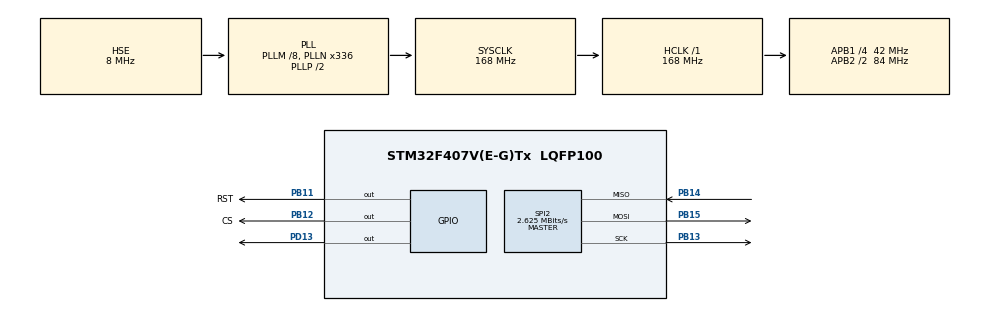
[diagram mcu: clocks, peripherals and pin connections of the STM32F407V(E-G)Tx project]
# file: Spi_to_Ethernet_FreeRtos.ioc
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FREERTOS.Tasks01=defaultTask,24,128,StartDefaultTask,Default,NULL,Dynamic,NULL,NULL
Mcu.Family=STM32F4
Mcu.Name=STM32F407V(E-G)Tx
Mcu.Package=LQFP100
NVIC.PriorityGroup=NVIC_PRIORITYGROUP_4
PA13.Mode=Trace_Asynchronous_SW
PA13.Signal=SYS_JTMS-SWDIO
PA14.Mode=Trace_Asynchronous_SW
PA14.Signal=SYS_JTCK-SWCLK
PB11.GPIO_Label=RST
PB11.GPIO_Speed=GPIO_SPEED_FREQ_HIGH
PB11.PinState=GPIO_PIN_SET
PB11.Signal=GPIO_Output
PB12.GPIO_Label=CS
PB12.GPIO_Speed=GPIO_SPEED_FREQ_HIGH
PB12.PinState=GPIO_PIN_SET
PB12.Signal=GPIO_Output
PB13.Mode=Full_Duplex_Master
PB13.Signal=SPI2_SCK
PB14.Mode=Full_Duplex_Master
PB14.Signal=SPI2_MISO
PB15.Mode=Full_Duplex_Master
PB15.Signal=SPI2_MOSI
PB3.Mode=Trace_Asynchronous_SW
PB3.Signal=SYS_JTDO-SWO
PD13.Signal=GPIO_Output
PH0-OSC_IN.Mode=HSE-External-Oscillator
PH0-OSC_IN.Signal=RCC_OSC_IN
PH1-OSC_OUT.Mode=HSE-External-Oscillator
PH1-OSC_OUT.Signal=RCC_OSC_OUT
ProjectManager.HeapSize=0x200
ProjectManager.StackSize=0x400
ProjectManager.TargetToolchain=STM32CubeIDE
RCC.48MHZClocksFreq_Value=48000000
RCC.AHBFreq_Value=168000000
RCC.APB1CLKDivider=RCC_HCLK_DIV4
RCC.APB1Freq_Value=42000000
RCC.APB1TimFreq_Value=84000000
RCC.APB2CLKDivider=RCC_HCLK_DIV2
RCC.APB2Freq_Value=84000000
RCC.APB2TimFreq_Value=168000000
RCC.CortexFreq_Value=168000000
RCC.HCLKFreq_Value=168000000
RCC.HSE_VALUE=8000000
RCC.HSI_VALUE=16000000
RCC.LSE_VALUE=32768
RCC.PLLM=8
RCC.PLLN=336
RCC.PLLQ=7
RCC.PLLSourceVirtual=RCC_PLLSOURCE_HSE
RCC.SYSCLKFreq_VALUE=168000000
RCC.SYSCLKSource=RCC_SYSCLKSOURCE_PLLCLK
RCC.VCOOutputFreq_Value=336000000
SPI2.BaudRatePrescaler=SPI_BAUDRATEPRESCALER_16
SPI2.CalculateBaudRate=2.625 MBits/s
SPI2.Direction=SPI_DIRECTION_2LINES
SPI2.Mode=SPI_MODE_MASTER
SPI2.VirtualType=VM_MASTER
VP_FREERTOS_VS_CMSIS_V2.Mode=CMSIS_V2
board=STM32F407G-DISC1

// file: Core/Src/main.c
/* USER CODE BEGIN Header */
/**
 ******************************************************************************
 * @file           : main.c
 * @brief          : Main program body
 ******************************************************************************
 * @attention
 *
 * Copyright (c) 2026 STMicroelectronics.
 * All rights reserved.
 *
 * This software is licensed under terms that can be found in the LICENSE file
 * in the root directory of this software component.
 * If no LICENSE file comes with this software, it is provided AS-IS.
 *
 ******************************************************************************
 */
/* USER CODE END Header */
#include "main.h"
#include "cmsis_os.h"

/* USER CODE BEGIN Includes */
#include "freertos.h"
#include "task.h"
#include "wizchip_conf.h"
#include "w5500.h"
#include "stdio.h"
#include "socket.h"
#include <string.h>
/* USER CODE END Includes */

SPI_HandleTypeDef hspi2;

/* Definitions for defaultTask */

/* USER CODE BEGIN PV */
TaskHandle_t T = NULL;
/* USER CODE END PV */

void SystemClock_Config(void);
static void MX_GPIO_Init(void);
static void MX_SPI2_Init(void);
void StartDefaultTask(void *argument);

/* USER CODE BEGIN 0 */
uint8_t tx ={'a'};

static void W5500_Select(void) {
	HAL_GPIO_WritePin(GPIOB, GPIO_PIN_12, GPIO_PIN_RESET);
}
static void W5500_Unselect(void) {
	HAL_GPIO_WritePin(GPIOB, GPIO_PIN_12, GPIO_PIN_SET);
}

static uint8_t W5500_ReadByte(void)
{
    uint8_t tx = 0xFF;
    uint8_t rx;

    HAL_SPI_TransmitReceive(&hspi2, &tx, &rx, 1, HAL_MAX_DELAY);

    return rx;
}

static void W5500_WriteByte(uint8_t tx) {
	HAL_SPI_Transmit(&hspi2, &tx, 1, HAL_MAX_DELAY);
}

static void W5500_ReadBuff(uint8_t *buff, uint16_t len)
{
    uint8_t dummy = 0xFF;

    while(len--)
    {
        HAL_SPI_TransmitReceive(&hspi2, &dummy, buff, 1, HAL_MAX_DELAY);
        buff++;
    }
}

static void W5500_WriteBuff(uint8_t *buff, uint16_t len) {
	HAL_SPI_Transmit(&hspi2, buff, len, HAL_MAX_DELAY);
}

static void W5500_Reset(void) {
	HAL_GPIO_WritePin(GPIOB, GPIO_PIN_11, GPIO_PIN_RESET);
	HAL_Delay(1000);
	HAL_GPIO_WritePin(GPIOB, GPIO_PIN_11, GPIO_PIN_SET);
	HAL_Delay(5);
}

int __io_putchar(int ch) { ITM_SendChar(ch); return ch; }

void ethertx(void *argument){
	uint8_t rxBuf[512]

	while(1)
	{
		switch(getSn_SR(0)) //// give connect in hercules then only entr the condiion ,whie debugging

			    {
			        case SOCK_ESTABLISHED:
			        {
			            static uint8_t sent = 0;

			            if(sent < 3)
			            {
			                char msg[] = "AJ\n\tData Arrived!!!\n";

			                send(0, (uint8_t *)msg, strlen(msg));

			                printf("AJ Sent\r\n");
			                sent ++;
			            }

			            break;
			        }

			        case SOCK_CLOSE_WAIT:
			            disconnect(0);
			            break;

			        case SOCK_CLOSED:
			            socket(0, Sn_MR_TCP, 5000, 0);
			            listen(0);
			            break;
			    }

       }
}

void Ether_init(void *argument){
	while(1)
	{	uint8_t tx_size[8] = { 2, 2, 2, 2, 2, 2, 2, 2 };
		uint8_t rx_size[8] = { 2, 2, 2, 2, 2, 2, 2, 2 };

		wiz_NetInfo net_info =
		{
		    .mac  = {0x00,0x08,0xDC,0x11,0x11,0x11},
		    .ip   = {192,168,5,50},
		    .sn   = {255,255,255,0},
		    .gw   = {192,168,5,1},
		    .dns  = {8,8,8,8},
		    .dhcp = NETINFO_STATIC
		};
	//
		W5500_Reset();

		reg_wizchip_cs_cbfunc(W5500_Select, W5500_Unselect);
		reg_wizchip_spi_cbfunc(W5500_ReadByte, W5500_WriteByte);
		reg_wizchip_spiburst_cbfunc(W5500_ReadBuff, W5500_WriteBuff);

		if (wizchip_init(tx_size, rx_size) == -1) {
			Error_Handler();
		}
		wizchip_setnetinfo(&net_info);
		uint8_t version = getVERSIONR();
		printf("VERSION = %d\r\n", version);
		wiz_NetInfo net;

		wizchip_getnetinfo(&net);

		printf("MAC : %02X:%02X:%02X:%02X:%02X:%02X\r\n",
		       net.mac[0], net.mac[1], net.mac[2],
		       net.mac[3], net.mac[4], net.mac[5]);

		printf("IP  : %d.%d.%d.%d\r\n",
		       net.ip[0], net.ip[1], net.ip[2], net.ip[3]);

		printf("SN  : %d.%d.%d.%d\r\n",
		       net.sn[0], net.sn[1], net.sn[2], net.sn[3]);

		printf("GW  : %d.%d.%d.%d\r\n",
		       net.gw[0], net.gw[1], net.gw[2], net.gw[3]);

		printf("DNS : %d.%d.%d.%d\r\n",
		       net.dns[0], net.dns[1], net.dns[2], net.dns[3]);
		uint8_t link_state;

		do
		{
		    ctlwizchip(CW_GET_PHYLINK, &link_state);
		    printf("PHY = %d\r\n", link_state);
		} while (link_state == PHY_LINK_OFF);

		printf("PHY = %d\r\n", link_state);
		socket(0, Sn_MR_TCP, 80, 0);
		listen(0);

		printf("TCP Server Started\r\n");
vTaskDelete(T);
	}
}
/* USER CODE END 0 */

int main(void)
{

  /* MCU Configuration--------------------------------------------------------*/

  /* Reset of all peripherals, Initializes the Flash interface and the Systick. */
  HAL_Init();

  /* Configure the system clock */
  SystemClock_Config();

  /* Initialize all configured peripherals */
  MX_GPIO_Init();
  MX_SPI2_Init();
  /* USER CODE BEGIN 2 */
  printf("printfworks\n");

  if (HAL_SPI_GetState(&hspi2) != HAL_SPI_STATE_READY)
  {
printf("fault\n");  }

xTaskCreate(Ether_init, "Ether_init", 100, NULL, 8, &T);
xTaskCreate(ethertx, "ethertx", 100, NULL, 7, NULL);
vTaskStartScheduler();
  /* USER CODE END 2 */

  /* Init scheduler */

  /* Create the thread(s) */
  /* creation of defaultTask */

  /* Start scheduler */

  /* We should never get here as control is now taken by the scheduler */

  /* Infinite loop */
	while (1) {

		}
}

void SystemClock_Config(void)
{
  RCC_OscInitTypeDef RCC_OscInitStruct = {0};
  RCC_ClkInitTypeDef RCC_ClkInitStruct = {0};

  /** Configure the main internal regulator output voltage
  */
  __HAL_RCC_PWR_CLK_ENABLE();
  __HAL_PWR_VOLTAGESCALING_CONFIG(PWR_REGULATOR_VOLTAGE_SCALE1);

  /** Initializes the RCC Oscillators according to the specified parameters
  * in the RCC_OscInitTypeDef structure.
  */
  RCC_OscInitStruct.OscillatorType = RCC_OSCILLATORTYPE_HSE;
  RCC_OscInitStruct.HSEState = RCC_HSE_ON;
  RCC_OscInitStruct.PLL.PLLState = RCC_PLL_ON;
  RCC_OscInitStruct.PLL.PLLSource = RCC_PLLSOURCE_HSE;
  RCC_OscInitStruct.PLL.PLLM = 8;
  RCC_OscInitStruct.PLL.PLLN = 336;
  RCC_OscInitStruct.PLL.PLLP = RCC_PLLP_DIV2;
  RCC_OscInitStruct.PLL.PLLQ = 7;
  if (HAL_RCC_OscConfig(&RCC_OscInitStruct) != HAL_OK)
  {
    Error_Handler();
  }

  /** Initializes the CPU, AHB and APB buses clocks
  */
  RCC_ClkInitStruct.ClockType = RCC_CLOCKTYPE_HCLK|RCC_CLOCKTYPE_SYSCLK
                              |RCC_CLOCKTYPE_PCLK1|RCC_CLOCKTYPE_PCLK2;
  RCC_ClkInitStruct.SYSCLKSource = RCC_SYSCLKSOURCE_PLLCLK;
  RCC_ClkInitStruct.AHBCLKDivider = RCC_SYSCLK_DIV1;
  RCC_ClkInitStruct.APB1CLKDivider = RCC_HCLK_DIV4;
  RCC_ClkInitStruct.APB2CLKDivider = RCC_HCLK_DIV2;

  if (HAL_RCC_ClockConfig(&RCC_ClkInitStruct, FLASH_LATENCY_5) != HAL_OK)
  {
    Error_Handler();
  }
}

static void MX_SPI2_Init(void)
{

  /* SPI2 parameter configuration*/
  hspi2.Instance = SPI2;
  hspi2.Init.Mode = SPI_MODE_MASTER;
  hspi2.Init.Direction = SPI_DIRECTION_2LINES;
  hspi2.Init.DataSize = SPI_DATASIZE_8BIT;
  hspi2.Init.CLKPolarity = SPI_POLARITY_LOW;
  hspi2.Init.CLKPhase = SPI_PHASE_1EDGE;
  hspi2.Init.NSS = SPI_NSS_SOFT;
  hspi2.Init.BaudRatePrescaler = SPI_BAUDRATEPRESCALER_16;
  hspi2.Init.FirstBit = SPI_FIRSTBIT_MSB;
  hspi2.Init.TIMode = SPI_TIMODE_DISABLE;
  hspi2.Init.CRCCalculation = SPI_CRCCALCULATION_DISABLE;
  hspi2.Init.CRCPolynomial = 10;
  if (HAL_SPI_Init(&hspi2) != HAL_OK)
  {
    Error_Handler();
  }

}

static void MX_GPIO_Init(void)
{
  GPIO_InitTypeDef GPIO_InitStruct = {0};

  /* GPIO Ports Clock Enable */
  __HAL_RCC_GPIOH_CLK_ENABLE();
  __HAL_RCC_GPIOB_CLK_ENABLE();
  __HAL_RCC_GPIOD_CLK_ENABLE();
  __HAL_RCC_GPIOA_CLK_ENABLE();

  /*Configure GPIO pin Output Level */
  HAL_GPIO_WritePin(GPIOB, RST_Pin|CS_Pin, GPIO_PIN_SET);

  /*Configure GPIO pin Output Level */
  HAL_GPIO_WritePin(GPIOD, GPIO_PIN_14, GPIO_PIN_RESET);

  /*Configure GPIO pins : RST_Pin CS_Pin */
  GPIO_InitStruct.Pin = RST_Pin|CS_Pin;
  GPIO_InitStruct.Mode = GPIO_MODE_OUTPUT_PP;
  GPIO_InitStruct.Pull = GPIO_NOPULL;
  GPIO_InitStruct.Speed = GPIO_SPEED_FREQ_HIGH;
  HAL_GPIO_Init(GPIOB, &GPIO_InitStruct);

  /*Configure GPIO pin : PD14 */
  GPIO_InitStruct.Pin = GPIO_PIN_14;
  GPIO_InitStruct.Mode = GPIO_MODE_OUTPUT_PP;
  GPIO_InitStruct.Pull = GPIO_NOPULL;
  GPIO_InitStruct.Speed = GPIO_SPEED_FREQ_LOW;
  HAL_GPIO_Init(GPIOD, &GPIO_InitStruct);

}

void StartDefaultTask(void *argument)
{
  for(;;)
  {
    osDelay(1);
  }
}

void Error_Handler(void)
{
	__disable_irq();
	while (1) {
	}
}
